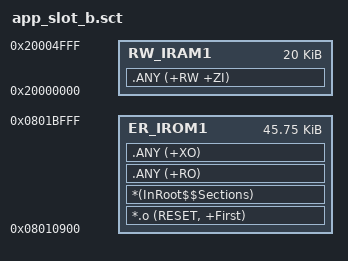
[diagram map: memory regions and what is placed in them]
; Application Slot B: 0x08010800 header + code at 0x08010900
; In Keil: Target options -> Linker -> Scatter File = this file
; also set IROM to 0x08010900 size 0xB700.
LR_IROM1 0x08010900 0x0000B700  {
  ER_IROM1 0x08010900 0x0000B700  {
   *.o (RESET, +First)
   *(InRoot$$Sections)
   .ANY (+RO)
   .ANY (+XO)
  }
  RW_IRAM1 0x20000000 0x00005000  {
   .ANY (+RW +ZI)
  }
}
